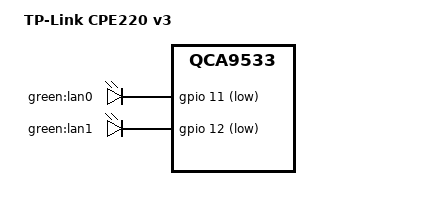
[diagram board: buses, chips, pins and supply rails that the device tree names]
// SPDX-License-Identifier: GPL-2.0-or-later OR MIT

#include "qca9533_tplink_cpexxx.dtsi"

/ {
	compatible = "tplink,cpe220-v3", "qca,qca9533";
	model = "TP-Link CPE220 v3";
};

&leds {
	lan0 {
		label = "green:lan0";
		gpios = <&gpio 11 GPIO_ACTIVE_LOW>;
	};

	lan1 {
		label = "green:lan1";
		gpios = <&gpio 12 GPIO_ACTIVE_LOW>;
	};
};

&eth1 {
	nvmem-cells = <&macaddr_info_8>;
	nvmem-cell-names = "mac-address";

	gmac-config {
		device = <&gmac>;
		switch-phy-swap = <0>;
		switch-only-mode = <1>;
	};
};
